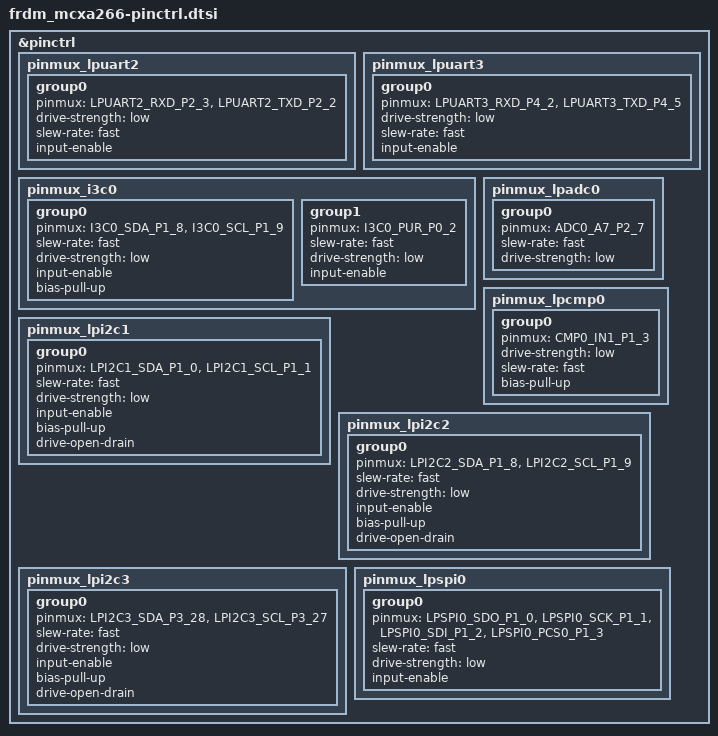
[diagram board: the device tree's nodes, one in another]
/*
 * Copyright 2025 NXP
 * SPDX-License-Identifier: Apache-2.0
 */


#include <nxp/mcx/MCXA266VLQ-pinctrl.h>

&pinctrl {
	pinmux_lpuart2: pinmux_lpuart2 {
		group0 {
			pinmux = <LPUART2_RXD_P2_3>,
				<LPUART2_TXD_P2_2>;
			drive-strength = "low";
			slew-rate = "fast";
			input-enable;
		};
	};

	pinmux_lpuart3: pinmux_lpuart3 {
		group0 {
			pinmux = <LPUART3_RXD_P4_2>,
				<LPUART3_TXD_P4_5>;
			drive-strength = "low";
			slew-rate = "fast";
			input-enable;
		};
	};

	pinmux_i3c0: pinmux_i3c0 {
		group0 {
			pinmux = <I3C0_SDA_P1_8>,
				<I3C0_SCL_P1_9>;
			slew-rate = "fast";
			drive-strength = "low";
			input-enable;
			bias-pull-up;
		};
		group1 {
			pinmux = <I3C0_PUR_P0_2>;
			slew-rate = "fast";
			drive-strength = "low";
			input-enable;
		};
	};
	pinmux_lpadc0: pinmux_lpadc0 {
		group0 {
			pinmux = <ADC0_A7_P2_7>;
			slew-rate = "fast";
			drive-strength = "low";
		};
	};
	pinmux_lpcmp0: pinmux_lpcmp0 {
		group0 {
			pinmux = <CMP0_IN1_P1_3>;
			drive-strength = "low";
			slew-rate = "fast";
			bias-pull-up;
		};
	};
	pinmux_lpi2c1: pinmux_lpi2c1 {
		group0 {
			pinmux = <LPI2C1_SDA_P1_0>,
			    <LPI2C1_SCL_P1_1>;
			slew-rate = "fast";
			drive-strength = "low";
			input-enable;
			bias-pull-up;
			drive-open-drain;
		};
	};
	pinmux_lpi2c2: pinmux_lpi2c2 {
		group0 {
			pinmux = <LPI2C2_SDA_P1_8>,
			    <LPI2C2_SCL_P1_9>;
			slew-rate = "fast";
			drive-strength = "low";
			input-enable;
			bias-pull-up;
			drive-open-drain;
		};
	};
	pinmux_lpi2c3: pinmux_lpi2c3 {
		group0 {
			pinmux = <LPI2C3_SDA_P3_28>,
			    <LPI2C3_SCL_P3_27>;
			slew-rate = "fast";
			drive-strength = "low";
			input-enable;
			bias-pull-up;
			drive-open-drain;
		};
	};

	pinmux_lpspi0: pinmux_lpspi0 {
		group0 {
			pinmux = <LPSPI0_SDO_P1_0>,
				 <LPSPI0_SCK_P1_1>,
				 <LPSPI0_SDI_P1_2>,
				 <LPSPI0_PCS0_P1_3>;
			slew-rate = "fast";
			drive-strength = "low";
			input-enable;
		};
	};
};
